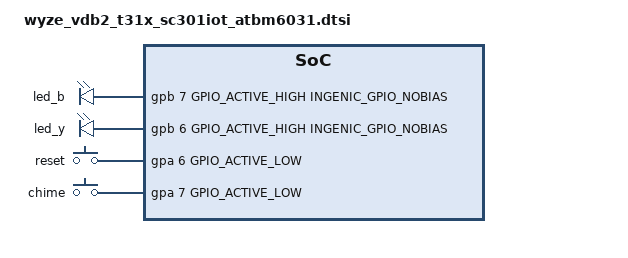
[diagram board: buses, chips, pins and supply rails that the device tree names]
// Wyze Video Doorbell v2 (T31X, SC301IoT, ATBM6031) per-board GPIO definitions.
// Injected into the kernel 4.4+ device tree; ignored on 3.10.

#include <dt-bindings/gpio/gpio.h>
#include <dt-bindings/input/input.h>
#include <dt-bindings/pinctrl/ingenic-pinctrl.h>

/ {
	gpio-leds {
		compatible = "gpio-leds";

		led_b {
			label = "led_b";
			gpios = <&gpb 7 GPIO_ACTIVE_HIGH INGENIC_GPIO_NOBIAS>;
			default-state = "off";
		};

		led_y {
			label = "led_y";
			gpios = <&gpb 6 GPIO_ACTIVE_HIGH INGENIC_GPIO_NOBIAS>;
			default-state = "off";
		};
	};
};

/* Card detect; the family tree carries the reference pin. */
&msc0 {
	ingenic,cd-gpios = <&gpb 16 GPIO_ACTIVE_LOW INGENIC_GPIO_PULLUP>;
};

/ {
	gpio-keys {
		compatible = "gpio-keys";
		label = "gpio-keys";

		reset {
			label = "reset";
			linux,code = <KEY_ENTER>;
			gpios = <&gpa 6 GPIO_ACTIVE_LOW INGENIC_GPIO_PULLUP>;
		};

		chime {
			label = "chime";
			linux,code = <KEY_1>;
			gpios = <&gpa 7 GPIO_ACTIVE_LOW INGENIC_GPIO_PULLUP>;
		};
	};
};
